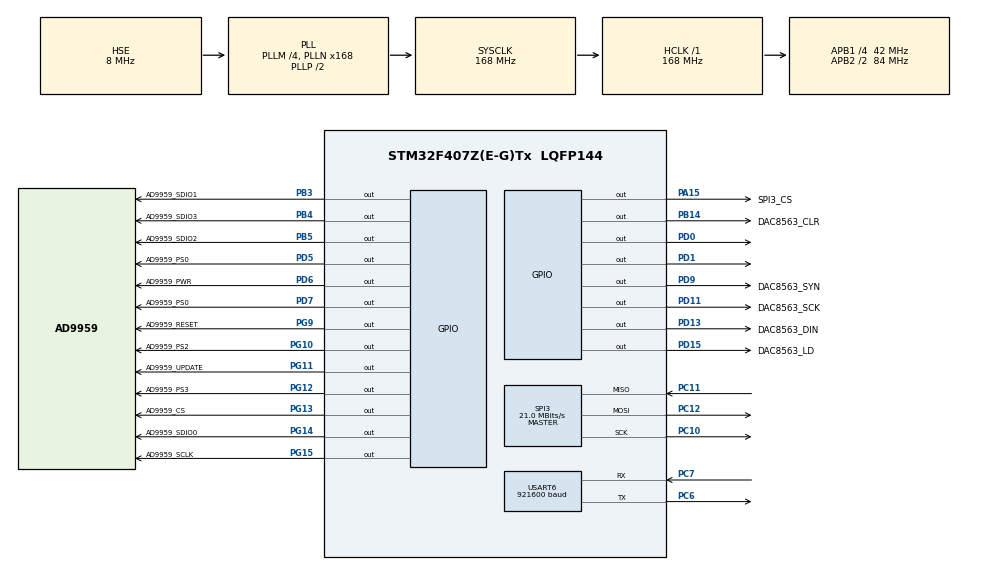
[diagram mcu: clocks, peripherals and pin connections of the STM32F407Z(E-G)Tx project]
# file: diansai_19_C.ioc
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Mcu.Family=STM32F4
PH0-OSC_IN.Signal=RCC_OSC_IN
RCC.CortexFreq_Value=168000000
SPI3.Direction=SPI_DIRECTION_2LINES
SPI3.VirtualType=VM_MASTER
PD15.GPIO_Speed=GPIO_SPEED_FREQ_VERY_HIGH
PC10.Signal=SPI3_SCK
PC12.Signal=SPI3_MOSI
PB14.GPIO_Label=DAC8563_CLR
PD9.GPIO_Speed=GPIO_SPEED_FREQ_VERY_HIGH
PG9.GPIO_Speed=GPIO_SPEED_FREQ_VERY_HIGH
PG13.Signal=GPIO_Output
PD6.GPIO_Label=AD9959_PWR
PB3.GPIO_Speed=GPIO_SPEED_FREQ_VERY_HIGH
PG11.Signal=GPIO_Output
PG15.Signal=GPIO_Output
RCC.SYSCLKSource=RCC_SYSCLKSOURCE_PLLCLK
ProjectManager.StackSize=0x400
PD13.Signal=GPIO_Output
PA15.GPIO_Label=SPI3_CS
PG15.GPIO_Label=AD9959_SCLK
PD11.GPIO_Label=DAC8563_SCK
RCC.HCLKFreq_Value=168000000
RCC.APB2TimFreq_Value=168000000
TIM3.Period=999
PC7.Signal=USART6_RX
PD0.Signal=GPIO_Output
RCC.AHBFreq_Value=168000000
PH0-OSC_IN.Mode=HSE-External-Oscillator
SPI3.DataSize=SPI_DATASIZE_16BIT
RCC.HSE_VALUE=8000000
PD7.GPIO_Speed=GPIO_SPEED_FREQ_VERY_HIGH
PG11.GPIO_Speed=GPIO_SPEED_FREQ_VERY_HIGH
PD0.PinState=GPIO_PIN_SET
PD1.GPIO_Speed=GPIO_SPEED_FREQ_VERY_HIGH
PA14.Mode=Serial_Wire
TIM3.Prescaler=83
TIM4.Period=9999
PA15.GPIO_ModeDefaultOutputPP=GPIO_MODE_OUTPUT_PP
VP_TIM1_VS_ClockSourceINT.Mode=Internal
PD7.GPIO_Label=AD9959_PS0
PH1-OSC_OUT.Mode=HSE-External-Oscillator
PD13.GPIO_Label=DAC8563_DIN
Mcu.Package=LQFP144
SPI3.Mode=SPI_MODE_MASTER
USART6.VirtualMode=VM_ASYNC
PG15.GPIO_Speed=GPIO_SPEED_FREQ_VERY_HIGH
PD5.GPIO_Label=AD9959_PS0
PA15.Signal=GPIO_Output
USART6.BaudRate=921600
PC11.Mode=Full_Duplex_Master
PB5.GPIO_Speed=GPIO_SPEED_FREQ_VERY_HIGH
RCC.APB2CLKDivider=RCC_HCLK_DIV2
PB5.GPIO_Label=AD9959_SDIO2
RCC.APB1TimFreq_Value=84000000
PD5.GPIO_Speed=GPIO_SPEED_FREQ_VERY_HIGH
PG11.GPIO_Label=AD9959_UPDATE
PG13.GPIO_Speed=GPIO_SPEED_FREQ_VERY_HIGH
TIM1.Period=5250
PD6.Signal=GPIO_Output
PD15.Signal=GPIO_Output
VP_TIM3_VS_ClockSourceINT.Mode=Internal
PB4.Signal=GPIO_Output
PG12.Signal=GPIO_Output
PB3.GPIO_Label=AD9959_SDIO1
RCC.PLLSourceVirtual=RCC_PLLSOURCE_HSE
PD15.GPIO_Label=DAC8563_LD
PD9.GPIO_Label=DAC8563_SYN
PG9.Signal=GPIO_Output
PC11.Signal=SPI3_MISO
PG13.PinState=GPIO_PIN_SET
PC6.Signal=USART6_TX
PC10.Mode=Full_Duplex_Master
PD7.Signal=GPIO_Output
PD1.Signal=GPIO_Output
PD9.Signal=GPIO_Output
PD5.Signal=GPIO_Output
PD1.GPIO_PuPd=GPIO_PULLUP
RCC.APB1CLKDivider=RCC_HCLK_DIV4
PG13.GPIO_Label=AD9959_CS
PG10.GPIO_Speed=GPIO_SPEED_FREQ_VERY_HIGH
PD0.GPIO_Speed=GPIO_SPEED_FREQ_VERY_HIGH
PG10.Signal=GPIO_Output
NVIC.USART6_IRQn=true\:0\:0\:false\:false\:true\:true\:true
PA13.Signal=SYS_JTMS-SWDIO
ProjectManager.TargetToolchain=STM32CubeIDE
PB14.GPIO_Speed=GPIO_SPEED_FREQ_VERY_HIGH
PC6.Mode=Asynchronous
PD11.GPIO_Speed=GPIO_SPEED_FREQ_VERY_HIGH
TIM4.Prescaler=83
RCC.LSE_VALUE=32768
PB14.Signal=GPIO_Output
PG9.GPIO_Label=AD9959_RESET
PG14.Signal=GPIO_Output
PC12.Mode=Full_Duplex_Master
board=custom
PD13.GPIO_Speed=GPIO_SPEED_FREQ_VERY_HIGH
SPI3.CLKPhase=SPI_PHASE_2EDGE
RCC.VCOOutputFreq_Value=336000000
NVIC.TIM3_IRQn=true\:0\:0\:false\:false\:true\:true\:true
PA15.PinState=GPIO_PIN_SET
PB4.GPIO_Speed=GPIO_SPEED_FREQ_VERY_HIGH
RCC.APB2Freq_Value=84000000
SPI3.CalculateBaudRate=21.0 MBits/s
PB4.GPIO_Label=AD9959_SDIO3
PH1-OSC_OUT.Signal=RCC_OSC_OUT
PA13.Mode=Serial_Wire
PG14.GPIO_Label=AD9959_SDIO0
Mcu.Name=STM32F407Z(E-G)Tx
RCC.48MHZClocksFreq_Value=84000000
PB3.Signal=GPIO_Output
RCC.SYSCLKFreq_VALUE=168000000
PB5.Signal=GPIO_Output
PD11.Signal=GPIO_Output
PA15.GPIO_Speed=GPIO_SPEED_FREQ_VERY_HIGH
PD1.PinState=GPIO_PIN_SET
PA14.Signal=SYS_JTCK-SWCLK
ProjectManager.HeapSize=0x200
PD0.GPIO_PuPd=GPIO_PULLUP
PG12.GPIO_Label=AD9959_PS3
PG12.GPIO_Speed=GPIO_SPEED_FREQ_VERY_HIGH
NVIC.TIM1_UP_TIM10_IRQn=true\:0\:0\:false\:false\:true\:true\:true
RCC.HSI_VALUE=16000000
VP_TIM4_VS_ClockSourceINT.Mode=Internal
NVIC.PriorityGroup=NVIC_PRIORITYGROUP_4
RCC.PLLM=4
RCC.PLLN=168
PC7.Mode=Asynchronous
NVIC.TIM4_IRQn=true\:0\:0\:false\:false\:true\:true\:true
RCC.APB1Freq_Value=42000000
PD6.GPIO_Speed=GPIO_SPEED_FREQ_VERY_HIGH
PG14.GPIO_Speed=GPIO_SPEED_FREQ_VERY_HIGH
PG10.GPIO_Label=AD9959_PS2

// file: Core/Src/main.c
/* USER CODE BEGIN Header */
/**
  ******************************************************************************
  * @file           : main.c
  * @brief          : Main program body
  ******************************************************************************
  * @attention
  *
  * <h2><center>&copy; Copyright (c) 2021 STMicroelectronics.
  * All rights reserved.</center></h2>
  *
  * This software component is licensed by ST under BSD 3-Clause license,
  * the "License"; You may not use this file except in compliance with the
  * License. You may obtain a copy of the License at:
  *                        opensource.org/licenses/BSD-3-Clause
  *
  ******************************************************************************
  */
/* USER CODE END Header */
#include "main.h"

/* USER CODE BEGIN PM */
arm_rfft_fast_instance_f32 S;//结构�???????
uint32_t count4=0;
uint32_t count3=0;
//float catch3[500];
float onedataCh1[512],onedataCh2[512];
float Z[201];
float sweepCh1[201],sweepCh2[201];
float Z500,Z500K;

float DACTest[20] = {0.0,1.545084971874737,2.938926261462366,4.045084971874737,4.755282581475767,5.0,4.755282581475768,4.045084971874737,2.9389262614623664,1.5450849718747375,6.123233995736766e-16,-1.5450849718747346,-2.938926261462365,-4.045084971874736,-4.755282581475767,-5.0,-4.755282581475768,-4.045084971874738,-2.938926261462367,-1.5450849718747384};

/* USER CODE END PM */

SPI_HandleTypeDef hspi3;

TIM_HandleTypeDef htim1;
TIM_HandleTypeDef htim3;
TIM_HandleTypeDef htim4;

UART_HandleTypeDef huart6;

void SystemClock_Config(void);
static void MX_GPIO_Init(void);
static void MX_SPI3_Init(void);
static void MX_TIM1_Init(void);
static void MX_USART6_UART_Init(void);
static void MX_TIM3_Init(void);
static void MX_TIM4_Init(void);

int main(void)
{

  /* MCU Configuration--------------------------------------------------------*/

  /* Reset of all peripherals, Initializes the Flash interface and the Systick. */
  HAL_Init();

  /* USER CODE BEGIN Init */
  arm_rfft_fast_init_f32(&S,1024);//初始化该结构�???????
  /* USER CODE END Init */

  /* Configure the system clock */
  SystemClock_Config();

  /* Initialize all configured peripherals */
  MX_GPIO_Init();
  MX_SPI3_Init();
  MX_TIM1_Init();
  MX_USART6_UART_Init();
  MX_TIM3_Init();
  MX_TIM4_Init();
  /* USER CODE BEGIN 2 */
  ADS8688_Init(&ads, &hspi3, SPI3_CS_GPIO_Port, SPI3_CS_Pin);
  Init_AD9959();
  HAL_Delay(21);
  //HAL_TIM_Base_Start_IT(&htim1);
  //TIM4->ARR = 39999;
  //HAL_UART_Receive_IT(TFT_RECEIVE, (uint8_t *)&R_onedata, 1);
  //HAL_TIM_Base_Start_IT(&htim4);
  //Write_frequence(0, 50000);

  DAC8563_Init();
  //HAL_TIM_Base_Start_IT(&htim3);
  DAC_OutAB(-10000, -10000);
  /* USER CODE END 2 */

  /* Infinite loop */
  while (1)
  {

  }
}

void SystemClock_Config(void)
{
  RCC_OscInitTypeDef RCC_OscInitStruct = {0};
  RCC_ClkInitTypeDef RCC_ClkInitStruct = {0};

  /** Configure the main internal regulator output voltage
  */
  __HAL_RCC_PWR_CLK_ENABLE();
  __HAL_PWR_VOLTAGESCALING_CONFIG(PWR_REGULATOR_VOLTAGE_SCALE1);
  /** Initializes the RCC Oscillators according to the specified parameters
  * in the RCC_OscInitTypeDef structure.
  */
  RCC_OscInitStruct.OscillatorType = RCC_OSCILLATORTYPE_HSE;
  RCC_OscInitStruct.HSEState = RCC_HSE_ON;
  RCC_OscInitStruct.PLL.PLLState = RCC_PLL_ON;
  RCC_OscInitStruct.PLL.PLLSource = RCC_PLLSOURCE_HSE;
  RCC_OscInitStruct.PLL.PLLM = 4;
  RCC_OscInitStruct.PLL.PLLN = 168;
  RCC_OscInitStruct.PLL.PLLP = RCC_PLLP_DIV2;
  RCC_OscInitStruct.PLL.PLLQ = 4;
  if (HAL_RCC_OscConfig(&RCC_OscInitStruct) != HAL_OK)
  {
    Error_Handler();
  }
  /** Initializes the CPU, AHB and APB buses clocks
  */
  RCC_ClkInitStruct.ClockType = RCC_CLOCKTYPE_HCLK|RCC_CLOCKTYPE_SYSCLK
                              |RCC_CLOCKTYPE_PCLK1|RCC_CLOCKTYPE_PCLK2;
  RCC_ClkInitStruct.SYSCLKSource = RCC_SYSCLKSOURCE_PLLCLK;
  RCC_ClkInitStruct.AHBCLKDivider = RCC_SYSCLK_DIV1;
  RCC_ClkInitStruct.APB1CLKDivider = RCC_HCLK_DIV4;
  RCC_ClkInitStruct.APB2CLKDivider = RCC_HCLK_DIV2;

  if (HAL_RCC_ClockConfig(&RCC_ClkInitStruct, FLASH_LATENCY_5) != HAL_OK)
  {
    Error_Handler();
  }
}

static void MX_SPI3_Init(void)
{

  /* SPI3 parameter configuration*/
  hspi3.Instance = SPI3;
  hspi3.Init.Mode = SPI_MODE_MASTER;
  hspi3.Init.Direction = SPI_DIRECTION_2LINES;
  hspi3.Init.DataSize = SPI_DATASIZE_16BIT;
  hspi3.Init.CLKPolarity = SPI_POLARITY_LOW;
  hspi3.Init.CLKPhase = SPI_PHASE_2EDGE;
  hspi3.Init.NSS = SPI_NSS_SOFT;
  hspi3.Init.BaudRatePrescaler = SPI_BAUDRATEPRESCALER_2;
  hspi3.Init.FirstBit = SPI_FIRSTBIT_MSB;
  hspi3.Init.TIMode = SPI_TIMODE_DISABLE;
  hspi3.Init.CRCCalculation = SPI_CRCCALCULATION_DISABLE;
  hspi3.Init.CRCPolynomial = 10;
  if (HAL_SPI_Init(&hspi3) != HAL_OK)
  {
    Error_Handler();
  }

}

static void MX_TIM1_Init(void)
{

  TIM_ClockConfigTypeDef sClockSourceConfig = {0};
  TIM_MasterConfigTypeDef sMasterConfig = {0};

  htim1.Instance = TIM1;
  htim1.Init.Prescaler = 0;
  htim1.Init.CounterMode = TIM_COUNTERMODE_UP;
  htim1.Init.Period = 5250;
  htim1.Init.ClockDivision = TIM_CLOCKDIVISION_DIV1;
  htim1.Init.RepetitionCounter = 0;
  htim1.Init.AutoReloadPreload = TIM_AUTORELOAD_PRELOAD_DISABLE;
  if (HAL_TIM_Base_Init(&htim1) != HAL_OK)
  {
    Error_Handler();
  }
  sClockSourceConfig.ClockSource = TIM_CLOCKSOURCE_INTERNAL;
  if (HAL_TIM_ConfigClockSource(&htim1, &sClockSourceConfig) != HAL_OK)
  {
    Error_Handler();
  }
  sMasterConfig.MasterOutputTrigger = TIM_TRGO_RESET;
  sMasterConfig.MasterSlaveMode = TIM_MASTERSLAVEMODE_DISABLE;
  if (HAL_TIMEx_MasterConfigSynchronization(&htim1, &sMasterConfig) != HAL_OK)
  {
    Error_Handler();
  }

}

static void MX_TIM3_Init(void)
{

  TIM_ClockConfigTypeDef sClockSourceConfig = {0};
  TIM_MasterConfigTypeDef sMasterConfig = {0};

  htim3.Instance = TIM3;
  htim3.Init.Prescaler = 83;
  htim3.Init.CounterMode = TIM_COUNTERMODE_UP;
  htim3.Init.Period = 999;
  htim3.Init.ClockDivision = TIM_CLOCKDIVISION_DIV1;
  htim3.Init.AutoReloadPreload = TIM_AUTORELOAD_PRELOAD_DISABLE;
  if (HAL_TIM_Base_Init(&htim3) != HAL_OK)
  {
    Error_Handler();
  }
  sClockSourceConfig.ClockSource = TIM_CLOCKSOURCE_INTERNAL;
  if (HAL_TIM_ConfigClockSource(&htim3, &sClockSourceConfig) != HAL_OK)
  {
    Error_Handler();
  }
  sMasterConfig.MasterOutputTrigger = TIM_TRGO_RESET;
  sMasterConfig.MasterSlaveMode = TIM_MASTERSLAVEMODE_DISABLE;
  if (HAL_TIMEx_MasterConfigSynchronization(&htim3, &sMasterConfig) != HAL_OK)
  {
    Error_Handler();
  }

}

static void MX_TIM4_Init(void)
{

  TIM_ClockConfigTypeDef sClockSourceConfig = {0};
  TIM_MasterConfigTypeDef sMasterConfig = {0};

  htim4.Instance = TIM4;
  htim4.Init.Prescaler = 83;
  htim4.Init.CounterMode = TIM_COUNTERMODE_UP;
  htim4.Init.Period = 9999;
  htim4.Init.ClockDivision = TIM_CLOCKDIVISION_DIV1;
  htim4.Init.AutoReloadPreload = TIM_AUTORELOAD_PRELOAD_DISABLE;
  if (HAL_TIM_Base_Init(&htim4) != HAL_OK)
  {
    Error_Handler();
  }
  sClockSourceConfig.ClockSource = TIM_CLOCKSOURCE_INTERNAL;
  if (HAL_TIM_ConfigClockSource(&htim4, &sClockSourceConfig) != HAL_OK)
  {
    Error_Handler();
  }
  sMasterConfig.MasterOutputTrigger = TIM_TRGO_RESET;
  sMasterConfig.MasterSlaveMode = TIM_MASTERSLAVEMODE_DISABLE;
  if (HAL_TIMEx_MasterConfigSynchronization(&htim4, &sMasterConfig) != HAL_OK)
  {
    Error_Handler();
  }

}

static void MX_USART6_UART_Init(void)
{

  huart6.Instance = USART6;
  huart6.Init.BaudRate = 921600;
  huart6.Init.WordLength = UART_WORDLENGTH_8B;
  huart6.Init.StopBits = UART_STOPBITS_1;
  huart6.Init.Parity = UART_PARITY_NONE;
  huart6.Init.Mode = UART_MODE_TX_RX;
  huart6.Init.HwFlowCtl = UART_HWCONTROL_NONE;
  huart6.Init.OverSampling = UART_OVERSAMPLING_16;
  if (HAL_UART_Init(&huart6) != HAL_OK)
  {
    Error_Handler();
  }

}

static void MX_GPIO_Init(void)
{
  GPIO_InitTypeDef GPIO_InitStruct = {0};

  /* GPIO Ports Clock Enable */
  __HAL_RCC_GPIOH_CLK_ENABLE();
  __HAL_RCC_GPIOB_CLK_ENABLE();
  __HAL_RCC_GPIOD_CLK_ENABLE();
  __HAL_RCC_GPIOC_CLK_ENABLE();
  __HAL_RCC_GPIOA_CLK_ENABLE();
  __HAL_RCC_GPIOG_CLK_ENABLE();

  /*Configure GPIO pin Output Level */
  HAL_GPIO_WritePin(GPIOB, DAC8563_CLR_Pin|AD9959_SDIO1_Pin|AD9959_SDIO3_Pin|AD9959_SDIO2_Pin, GPIO_PIN_RESET);

  /*Configure GPIO pin Output Level */
  HAL_GPIO_WritePin(GPIOD, DAC8563_SYN_Pin|DAC8563_SCK_Pin|DAC8563_DIN_Pin|DAC8563_LD_Pin
                          |AD9959_PS0_Pin|AD9959_PWR_Pin|AD9959_PS0D7_Pin, GPIO_PIN_RESET);

  /*Configure GPIO pin Output Level */
  HAL_GPIO_WritePin(SPI3_CS_GPIO_Port, SPI3_CS_Pin, GPIO_PIN_SET);

  /*Configure GPIO pin Output Level */
  HAL_GPIO_WritePin(GPIOD, GPIO_PIN_0|GPIO_PIN_1, GPIO_PIN_SET);

  /*Configure GPIO pin Output Level */
  HAL_GPIO_WritePin(GPIOG, AD9959_RESET_Pin|AD9959_PS2_Pin|AD9959_UPDATE_Pin|AD9959_PS3_Pin
                          |AD9959_SDIO0_Pin|AD9959_SCLK_Pin, GPIO_PIN_RESET);

  /*Configure GPIO pin Output Level */
  HAL_GPIO_WritePin(AD9959_CS_GPIO_Port, AD9959_CS_Pin, GPIO_PIN_SET);

  /*Configure GPIO pins : DAC8563_CLR_Pin AD9959_SDIO1_Pin AD9959_SDIO3_Pin AD9959_SDIO2_Pin */
  GPIO_InitStruct.Pin = DAC8563_CLR_Pin|AD9959_SDIO1_Pin|AD9959_SDIO3_Pin|AD9959_SDIO2_Pin;
  GPIO_InitStruct.Mode = GPIO_MODE_OUTPUT_PP;
  GPIO_InitStruct.Pull = GPIO_NOPULL;
  GPIO_InitStruct.Speed = GPIO_SPEED_FREQ_VERY_HIGH;
  HAL_GPIO_Init(GPIOB, &GPIO_InitStruct);

  /*Configure GPIO pins : DAC8563_SYN_Pin DAC8563_SCK_Pin DAC8563_DIN_Pin DAC8563_LD_Pin
                           AD9959_PS0_Pin AD9959_PWR_Pin AD9959_PS0D7_Pin */
  GPIO_InitStruct.Pin = DAC8563_SYN_Pin|DAC8563_SCK_Pin|DAC8563_DIN_Pin|DAC8563_LD_Pin
                          |AD9959_PS0_Pin|AD9959_PWR_Pin|AD9959_PS0D7_Pin;
  GPIO_InitStruct.Mode = GPIO_MODE_OUTPUT_PP;
  GPIO_InitStruct.Pull = GPIO_NOPULL;
  GPIO_InitStruct.Speed = GPIO_SPEED_FREQ_VERY_HIGH;
  HAL_GPIO_Init(GPIOD, &GPIO_InitStruct);

  /*Configure GPIO pin : SPI3_CS_Pin */
  GPIO_InitStruct.Pin = SPI3_CS_Pin;
  GPIO_InitStruct.Mode = GPIO_MODE_OUTPUT_PP;
  GPIO_InitStruct.Pull = GPIO_NOPULL;
  GPIO_InitStruct.Speed = GPIO_SPEED_FREQ_VERY_HIGH;
  HAL_GPIO_Init(SPI3_CS_GPIO_Port, &GPIO_InitStruct);

  /*Configure GPIO pins : PD0 PD1 */
  GPIO_InitStruct.Pin = GPIO_PIN_0|GPIO_PIN_1;
  GPIO_InitStruct.Mode = GPIO_MODE_OUTPUT_PP;
  GPIO_InitStruct.Pull = GPIO_PULLUP;
  GPIO_InitStruct.Speed = GPIO_SPEED_FREQ_VERY_HIGH;
  HAL_GPIO_Init(GPIOD, &GPIO_InitStruct);

  /*Configure GPIO pins : AD9959_RESET_Pin AD9959_PS2_Pin AD9959_UPDATE_Pin AD9959_PS3_Pin
                           AD9959_CS_Pin AD9959_SDIO0_Pin AD9959_SCLK_Pin */
  GPIO_InitStruct.Pin = AD9959_RESET_Pin|AD9959_PS2_Pin|AD9959_UPDATE_Pin|AD9959_PS3_Pin
                          |AD9959_CS_Pin|AD9959_SDIO0_Pin|AD9959_SCLK_Pin;
  GPIO_InitStruct.Mode = GPIO_MODE_OUTPUT_PP;
  GPIO_InitStruct.Pull = GPIO_NOPULL;
  GPIO_InitStruct.Speed = GPIO_SPEED_FREQ_VERY_HIGH;
  HAL_GPIO_Init(GPIOG, &GPIO_InitStruct);

}

void Error_Handler(void)
{
  __disable_irq();
  while (1)
  {
  }
}

/************************ (C) COPYRIGHT STMicroelectronics *****END OF FILE****/
